# APM32F411 register map
Vendor: Geehy; File version: 2024.11.05
CPU: CM4 r1p0, little endian, 3 interrupt priority bits
Registers are 32-bit, read-write, reset 0x0 unless marked. A register's access mark holds for its fields unless they carry their own. Offsets are from the block's base; [hi:lo] are bit positions; {n}, {i} and the like mark numbered series.

## WWDT — Window watchdog
Base 0x40002C00
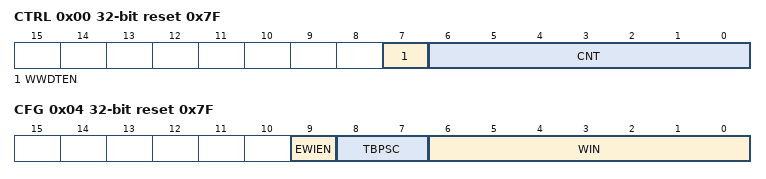
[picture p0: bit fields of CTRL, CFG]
0x00 CTRL reset 0x7F — Control register
  [7] WWDTEN — Activation bit
  [6:0] CNT — 7-bit counter (MSB to LSB)
0x04 CFG reset 0x7F — Configuration register
  [9] EWIEN — Early wakeup interrupt
  [8:7] TBPSC — Timer Base Prescaler Factor Configure
  [6:0] WIN — 7-bit window value
0x08 STS — Status register
  [0] EWIFLG — Early wakeup interrupt flag

## SCnSCB — System Controls not in SCB
Base 0xE000E000
0x04 ICTR ro — Interrupt Controller Type Register
  [3:0] INTLINESNUM — Indicates the number of interrupt lines implemented
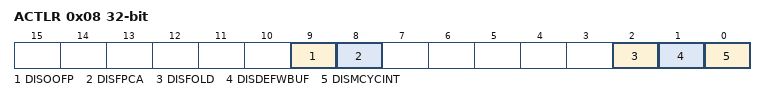
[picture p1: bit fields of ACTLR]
0x08 ACTLR — Auxiliary Control Register
  [9] DISOOFP — Disables out-of-order floating-point instruction completion
  [8] DISFPCA — Disables the FPCA bit in the CONTROL register
  [2] DISFOLD — Disables folding of IT instructions
  [1] DISDEFWBUF — Disables write buffer use during default memory map
  [0] DISMCYCINT — Disables interruption of multi-cycle instructions

## SysTick — System Tick Timer
Base 0xE000E010
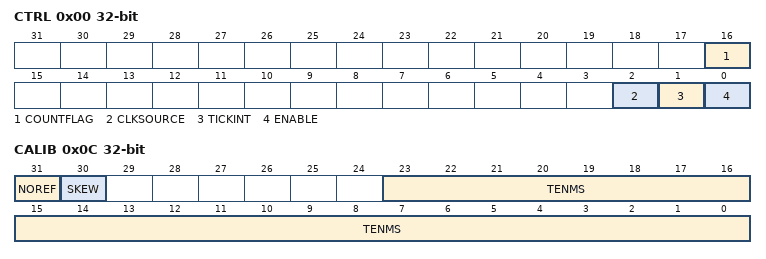
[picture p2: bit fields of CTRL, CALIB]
0x00 CTRL — SysTick Control and Status Register (aka SYST_CSR)
  [16] COUNTFLAG — Indicates if the counter reached 0
  [2] CLKSOURCE — Indicates the clock source
  [1] TICKINT — Enables the SysTick exception
  [0] ENABLE — Enables the counter
0x04 LOAD — SysTick Reload Value Register (aka SYST_RVR)
  [23:0] RELOAD — Value to load into the SysTick counter
0x08 VAL — SysTick Current Value Register (aka SYST_CVR)
  [23:0] CURRENT — Current value of the SysTick counter
0x0C CALIB ro — SysTick Calibration Register (aka SYST_CALIB)
  [31] NOREF — Indicates whether the reference clock is implemented
  [30] SKEW — Indicates whether the calibration value is exact
  [23:0] TENMS — Indicates the number of clock cycles for 10ms

## ITM — Instrumentation Trace Macrocell
Base 0xE0000000
{0x0+4i} PORT{i} (i=0..31) wo reset not defined — ITM Stimulus Port Registers (aka ITM_STIMx)
  [31:0] DATA — Data written to the stimulus port
0xE00 TER — ITM Trace Enable Register (aka ITM_TERx)
  [31:0] ENABLED — Trace enable bits for each stimulus port
0xE40 TPR — ITM Trace Privilege Register
  [31:0] PRIVMASK — Privilege mask for access control
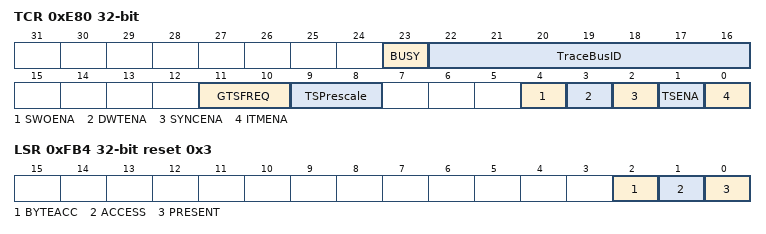
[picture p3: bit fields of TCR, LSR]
0xE80 TCR — ITM Trace Control Register
  [23] BUSY — Indicates if ITM is busy
  [22:16] TraceBusID
  [11:10] GTSFREQ — Global timestamp frequency
  [9:8] TSPrescale — Timestamp prescaler
  [4] SWOENA — SWO output enable
  [3] DWTENA — DWT event enable (aka TXENA)
  [2] SYNCENA — Synchronization enable
  [1] TSENA — Timestamp enable
  [0] ITMENA — ITM enable
0xFB0 LAR wo — ITM Lock Access Register
  [31:0] ACCESS — Write access to unlock ITM
0xFB4 LSR ro reset 0x3 — ITM Lock Status Register
  [2] BYTEACC — Indicates byte access capability
  [1] ACCESS — Indicates access status
  [0] PRESENT — Indicates ITM presence
{0xFD0+4i} PID{i} (i=0..7) ro reset not defined — Peripheral Identification Registers
  [31:0] VALUE — Peripheral identification value
{0xFF0+4i} CID{i} (i=0..3) ro reset not defined — Component Identification Registers
  [31:0] VALUE — Component identification value

## DWT — Data Watchpoint and Trace
Base 0xE0001000
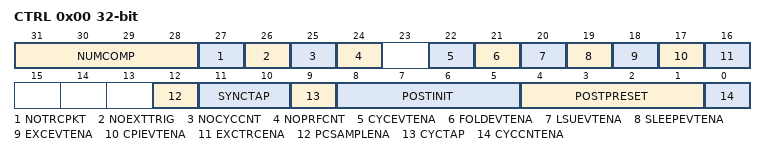
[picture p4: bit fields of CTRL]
0x00 CTRL — Control Register
  [31:28] NUMCOMP — Number of comparators implemented
  [27] NOTRCPKT — Indicates no trace packets are implemented
  [26] NOEXTTRIG — Indicates no external match trigger is implemented
  [25] NOCYCCNT — Indicates no cycle counter is implemented
  [24] NOPRFCNT — Indicates no profiling counters are implemented
  [22] CYCEVTENA — Enables cycle event
  [21] FOLDEVTENA — Enables folded instruction event
  [20] LSUEVTENA — Enables LSU counter event
  [19] SLEEPEVTENA — Enables sleep event
  [18] EXCEVTENA — Enables exception overhead event
  [17] CPIEVTENA — Enables CPI counter event
  [16] EXCTRCENA — Enables exception tracing
  [12] PCSAMPLENA — Enables program counter sampling
  [11:10] SYNCTAP — Synchronization tap
  [9] CYCTAP — Cycle count tap
  [8:5] POSTINIT — Post-initialization value
  [4:1] POSTPRESET — Post-scaler preset value
  [0] CYCCNTENA — Enables cycle counter
0x04 CYCCNT — Cycle Count Register
  [31:0] CYCCNT — Cycle counter value
0x08 CPICNT — CPI Count Register
  [7:0] CPICNT — CPI counter value
0x0C EXCCNT — Exception Overhead Count Register
  [7:0] EXCCNT — Exception overhead counter value
0x10 SLEEPCNT — Sleep Count Register
  [7:0] SLEEPCNT — Sleep counter value
0x14 LSUCNT — LSU Count Register
  [7:0] LSUCNT — LSU counter value
0x18 FOLDCNT — Folded-instruction Count Register
  [7:0] FOLDCNT — Folded-instruction counter value
0x1C PCSR ro — Program Counter Sample Register
  [31:0] PCSR — Program counter sample value
{0x20+0x10*i} COMP{i} (i=0..3) reset not defined — Comparator Registers
  [31:0] COMP — Comparator value
{0x24+0x10*i} MASK{i} (i=0..3) reset not defined — Mask Registers
  [4:0] MASK — Mask value
{0x28+0x10*i} FUNCTION{i} (i=0..3) reset not defined — Function Registers
  [31:0] FUNCTION — Function settings
